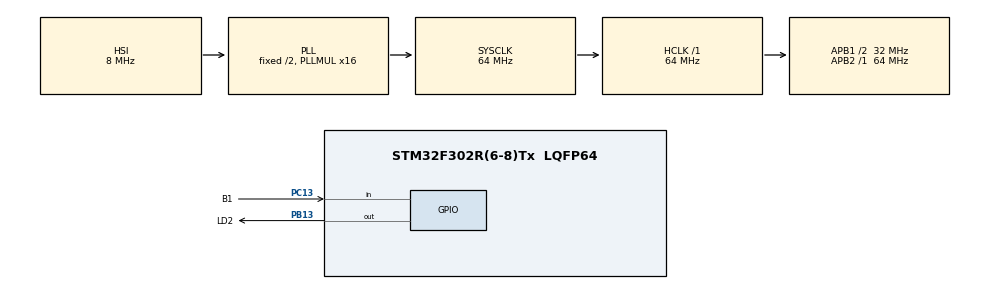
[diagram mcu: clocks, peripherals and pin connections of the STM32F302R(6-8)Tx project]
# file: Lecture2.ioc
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Mcu.Family=STM32F3
Mcu.Name=STM32F302R(6-8)Tx
Mcu.Package=LQFP64
NVIC.PriorityGroup=NVIC_PRIORITYGROUP_0
PA13.Mode=Serial_Wire
PA13.Signal=SYS_JTMS-SWDIO
PA14.Mode=Serial_Wire
PA14.Signal=SYS_JTCK-SWCLK
PB13.GPIO_Label=LD2
PB13.Signal=GPIO_Output
PC13.GPIO_Label=B1
PC13.GPIO_PuPd=GPIO_PULLUP
PC13.Signal=GPIO_Input
PC14\ -\ OSC32_IN.Mode=LSE-External-Oscillator
PC14\ -\ OSC32_IN.Signal=RCC_OSC32_IN
PC15\ -\ OSC32_OUT.Mode=LSE-External-Oscillator
PC15\ -\ OSC32_OUT.Signal=RCC_OSC32_OUT
PF0-OSC_IN.Mode=HSE-External-Clock-Source
PF0-OSC_IN.Signal=RCC_OSC_IN
ProjectManager.HeapSize=0x200
ProjectManager.StackSize=0x400
ProjectManager.TargetToolchain=STM32CubeIDE
RCC.AHBFreq_Value=64000000
RCC.APB1CLKDivider=RCC_HCLK_DIV2
RCC.APB1Freq_Value=32000000
RCC.APB1TimFreq_Value=64000000
RCC.APB2Freq_Value=64000000
RCC.APB2TimFreq_Value=64000000
RCC.CortexFreq_Value=64000000
RCC.HCLKFreq_Value=64000000
RCC.HSE_VALUE=8000000
RCC.HSI_VALUE=8000000
RCC.PLLM=8
RCC.PLLMUL=RCC_PLL_MUL16
RCC.PLLN=336
RCC.PLLP=RCC_PLLP_DIV4
RCC.PLLQ=7
RCC.RCC_PLLsource_Clock_Source_FROM_HSE=RCC_HSE_PREDIV_DIV2
RCC.SYSCLKFreq_VALUE=64000000
RCC.SYSCLKSourceVirtual=RCC_SYSCLKSOURCE_PLLCLK
RCC.USBFreq_Value=64000000
board=NUCLEO-F302R8

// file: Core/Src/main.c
/* USER CODE BEGIN Header */
/**
  ******************************************************************************
  * @file           : main.c
  * @brief          : Main program body
  ******************************************************************************
  * @attention
  *
  * Copyright (c) 2026 STMicroelectronics.
  * All rights reserved.
  *
  * This software is licensed under terms that can be found in the LICENSE file
  * in the root directory of this software component.
  * If no LICENSE file comes with this software, it is provided AS-IS.
  *
  ******************************************************************************
  */
/* USER CODE END Header */
#include "main.h"
#include "gpio.h"

void SystemClock_Config(void);

int main(void)
{

  /* USER CODE BEGIN 1 */
  GPIO_PinState state = GPIO_PIN_SET;

  /* USER CODE END 1 */

  /* MCU Configuration--------------------------------------------------------*/

  /* Reset of all peripherals, Initializes the Flash interface and the Systick. */
  HAL_Init();

  /* Configure the system clock */
  SystemClock_Config();

  /* Initialize all configured peripherals */
  MX_GPIO_Init();

  /* Infinite loop */
  /* USER CODE BEGIN WHILE */
  while (1)
  {
	state = HAL_GPIO_ReadPin(B1_GPIO_Port, B1_Pin);
	// The state is flipped, so if pushed then state is RESET.
	// Therefore, when not pushed state is SET.
	state = (GPIO_PinState) ((state + 1U) % 2U);
	HAL_GPIO_WritePin(LD2_GPIO_Port, LD2_Pin, state);
	// I chose to add some delay because there seems to be
	// some small jitter.
	HAL_Delay(100);
    /* USER CODE END WHILE */
  }
}

void SystemClock_Config(void)
{
  RCC_OscInitTypeDef RCC_OscInitStruct = {0};
  RCC_ClkInitTypeDef RCC_ClkInitStruct = {0};

  /** Initializes the RCC Oscillators according to the specified parameters
  * in the RCC_OscInitTypeDef structure.
  */
  RCC_OscInitStruct.OscillatorType = RCC_OSCILLATORTYPE_HSI;
  RCC_OscInitStruct.HSIState = RCC_HSI_ON;
  RCC_OscInitStruct.HSICalibrationValue = RCC_HSICALIBRATION_DEFAULT;
  RCC_OscInitStruct.PLL.PLLState = RCC_PLL_ON;
  RCC_OscInitStruct.PLL.PLLSource = RCC_PLLSOURCE_HSI;
  RCC_OscInitStruct.PLL.PLLMUL = RCC_PLL_MUL16;
  if (HAL_RCC_OscConfig(&RCC_OscInitStruct) != HAL_OK)
  {
    Error_Handler();
  }

  /** Initializes the CPU, AHB and APB buses clocks
  */
  RCC_ClkInitStruct.ClockType = RCC_CLOCKTYPE_HCLK|RCC_CLOCKTYPE_SYSCLK
                              |RCC_CLOCKTYPE_PCLK1|RCC_CLOCKTYPE_PCLK2;
  RCC_ClkInitStruct.SYSCLKSource = RCC_SYSCLKSOURCE_PLLCLK;
  RCC_ClkInitStruct.AHBCLKDivider = RCC_SYSCLK_DIV1;
  RCC_ClkInitStruct.APB1CLKDivider = RCC_HCLK_DIV2;
  RCC_ClkInitStruct.APB2CLKDivider = RCC_HCLK_DIV1;

  if (HAL_RCC_ClockConfig(&RCC_ClkInitStruct, FLASH_LATENCY_2) != HAL_OK)
  {
    Error_Handler();
  }
}

void Error_Handler(void)
{
  __disable_irq();
  while (1)
  {
  }
}
